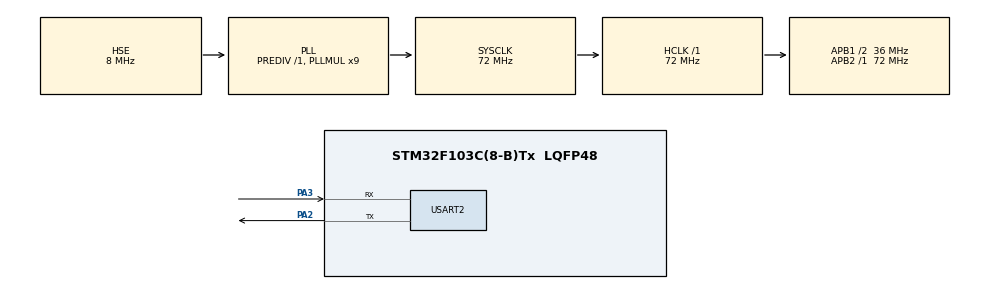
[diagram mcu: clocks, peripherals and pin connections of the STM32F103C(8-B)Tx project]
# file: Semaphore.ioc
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FREERTOS.BinarySemaphores01=myBinarySem01,Dynamic,NULL
FREERTOS.Tasks01=defaultTask,0,128,StartDefaultTask,Default,NULL,Dynamic,NULL,NULL
FREERTOS.configUSE_COUNTING_SEMAPHORES=1
Mcu.Family=STM32F1
Mcu.Name=STM32F103C(8-B)Tx
Mcu.Package=LQFP48
NVIC.PriorityGroup=NVIC_PRIORITYGROUP_4
NVIC.TIM4_IRQn=true\:0\:0\:false\:false\:true\:false\:false\:true
NVIC.TimeBase=TIM4_IRQn
NVIC.TimeBaseIP=TIM4
NVIC.USART2_IRQn=true\:5\:0\:false\:false\:true\:true\:true\:true
PA13.Mode=Serial_Wire
PA13.Signal=SYS_JTMS-SWDIO
PA14.Mode=Serial_Wire
PA14.Signal=SYS_JTCK-SWCLK
PA2.Mode=Asynchronous
PA2.Signal=USART2_TX
PA3.Mode=Asynchronous
PA3.Signal=USART2_RX
PD0-OSC_IN.Mode=HSE-External-Oscillator
PD0-OSC_IN.Signal=RCC_OSC_IN
PD1-OSC_OUT.Mode=HSE-External-Oscillator
PD1-OSC_OUT.Signal=RCC_OSC_OUT
ProjectManager.HeapSize=0x200
ProjectManager.StackSize=0x400
ProjectManager.TargetToolchain=MDK-ARM V5.27
RCC.AHBFreq_Value=72000000
RCC.APB1CLKDivider=RCC_HCLK_DIV2
RCC.APB1Freq_Value=36000000
RCC.APB1TimFreq_Value=72000000
RCC.APB2Freq_Value=72000000
RCC.APB2TimFreq_Value=72000000
RCC.HCLKFreq_Value=72000000
RCC.PLLMUL=RCC_PLL_MUL9
RCC.PLLSourceVirtual=RCC_PLLSOURCE_HSE
RCC.SYSCLKFreq_VALUE=72000000
RCC.SYSCLKSource=RCC_SYSCLKSOURCE_PLLCLK
RCC.USBFreq_Value=72000000
USART2.VirtualMode=VM_ASYNC
VP_FREERTOS_VS_CMSIS_V1.Mode=CMSIS_V1
VP_SYS_VS_tim4.Mode=TIM4
board=custom

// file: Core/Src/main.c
/* USER CODE BEGIN Header */
/* USER CODE END Header */
#include "main.h"
#include "cmsis_os.h"

/* USER CODE BEGIN Includes */
#include <stdio.h>
/* USER CODE END Includes */

UART_HandleTypeDef huart2;

osThreadId defaultTaskHandle;
osSemaphoreId myBinarySem01Handle;
/* USER CODE BEGIN PV */
osSemaphoreId CountingSemHandle;
xTaskHandle AboveNormalHandle;
xTaskHandle HighHandle;
/* USER CODE END PV */

void SystemClock_Config(void);
static void MX_GPIO_Init(void);
static void MX_USART2_UART_Init(void);
void StartDefaultTask(void const * argument);

/* USER CODE BEGIN PFP */
void AboveNormalTask(void *arg);
void HighTask(void *arg);
/* USER CODE END PFP */

/* USER CODE BEGIN 0 */
#ifdef __GNUC__
#define PUTCHAR_PROTOTYPE int __io_putchar(int ch)
#else
#define PUTCHAR_PROTOTYPE int fputc(int ch, FILE *f)
#endif /* __GNUC__ */

/**
  * @brief  Retargets the C library printf function to the USART.
  * @param  None
  * @retval None
  */
PUTCHAR_PROTOTYPE
{
  HAL_UART_Transmit(&huart2, (uint8_t *)&ch, 1, HAL_MAX_DELAY);
  return ch;
}

char data;
/* USER CODE END 0 */

int main(void)
{

  /* MCU Configuration--------------------------------------------------------*/

  /* Reset of all peripherals, Initializes the Flash interface and the Systick. */
  HAL_Init();

  /* Configure the system clock */
  SystemClock_Config();

  /* Initialize all configured peripherals */
  MX_GPIO_Init();
  MX_USART2_UART_Init();
  /* USER CODE BEGIN 2 */
  HAL_UART_Receive_IT(&huart2, (uint8_t *)&data, 1);
  /* USER CODE END 2 */

  /* Create the semaphores(s) */
  /* definition and creation of myBinarySem01 */
  osSemaphoreDef(myBinarySem01);
  myBinarySem01Handle = osSemaphoreCreate(osSemaphore(myBinarySem01), 1);

  /* USER CODE BEGIN RTOS_SEMAPHORES */
  osSemaphoreDef(CoutingSem01);
  CountingSemHandle = osSemaphoreCreate(osSemaphore(CoutingSem01), 3);
  /* add semaphores, ... */
  /* USER CODE END RTOS_SEMAPHORES */

  /* Create the thread(s) */
  /* definition and creation of defaultTask */
  osThreadDef(defaultTask, StartDefaultTask, osPriorityNormal, 0, 128);
  defaultTaskHandle = osThreadCreate(osThread(defaultTask), NULL);

  /* USER CODE BEGIN RTOS_THREADS */
  xTaskCreate(AboveNormalTask, "Task2", 128, NULL, 3 + osPriorityAboveNormal, &AboveNormalHandle);
  xTaskCreate(HighTask, "Task3", 128, NULL, 3+ osPriorityHigh, &HighHandle);

  /* add threads, ... */
  /* USER CODE END RTOS_THREADS */

  /* Start scheduler */
  osKernelStart();

  /* We should never get here as control is now taken by the scheduler */
  /* Infinite loop */

}

void SystemClock_Config(void)
{
  RCC_OscInitTypeDef RCC_OscInitStruct = {0};
  RCC_ClkInitTypeDef RCC_ClkInitStruct = {0};

  /** Initializes the RCC Oscillators according to the specified parameters
  * in the RCC_OscInitTypeDef structure.
  */
  RCC_OscInitStruct.OscillatorType = RCC_OSCILLATORTYPE_HSE;
  RCC_OscInitStruct.HSEState = RCC_HSE_ON;
  RCC_OscInitStruct.HSEPredivValue = RCC_HSE_PREDIV_DIV1;
  RCC_OscInitStruct.HSIState = RCC_HSI_ON;
  RCC_OscInitStruct.PLL.PLLState = RCC_PLL_ON;
  RCC_OscInitStruct.PLL.PLLSource = RCC_PLLSOURCE_HSE;
  RCC_OscInitStruct.PLL.PLLMUL = RCC_PLL_MUL9;
  if (HAL_RCC_OscConfig(&RCC_OscInitStruct) != HAL_OK)
  {
    Error_Handler();
  }
  /** Initializes the CPU, AHB and APB buses clocks
  */
  RCC_ClkInitStruct.ClockType = RCC_CLOCKTYPE_HCLK|RCC_CLOCKTYPE_SYSCLK
                              |RCC_CLOCKTYPE_PCLK1|RCC_CLOCKTYPE_PCLK2;
  RCC_ClkInitStruct.SYSCLKSource = RCC_SYSCLKSOURCE_PLLCLK;
  RCC_ClkInitStruct.AHBCLKDivider = RCC_SYSCLK_DIV1;
  RCC_ClkInitStruct.APB1CLKDivider = RCC_HCLK_DIV2;
  RCC_ClkInitStruct.APB2CLKDivider = RCC_HCLK_DIV1;

  if (HAL_RCC_ClockConfig(&RCC_ClkInitStruct, FLASH_LATENCY_2) != HAL_OK)
  {
    Error_Handler();
  }
}

static void MX_USART2_UART_Init(void)
{

  huart2.Instance = USART2;
  huart2.Init.BaudRate = 115200;
  huart2.Init.WordLength = UART_WORDLENGTH_8B;
  huart2.Init.StopBits = UART_STOPBITS_1;
  huart2.Init.Parity = UART_PARITY_NONE;
  huart2.Init.Mode = UART_MODE_TX_RX;
  huart2.Init.HwFlowCtl = UART_HWCONTROL_NONE;
  huart2.Init.OverSampling = UART_OVERSAMPLING_16;
  if (HAL_UART_Init(&huart2) != HAL_OK)
  {
    Error_Handler();
  }

}

static void MX_GPIO_Init(void)
{

  /* GPIO Ports Clock Enable */
  __HAL_RCC_GPIOD_CLK_ENABLE();
  __HAL_RCC_GPIOA_CLK_ENABLE();

}

/* USER CODE BEGIN 4 */

void HAL_UART_RxCpltCallback(UART_HandleTypeDef *huart)
{
  if(huart->Instance == huart2.Instance)
  {
    HAL_UART_Receive_IT(&huart2, (uint8_t *)&data, 1);
    switch (data)
    {
    case '1':
      osSemaphoreRelease(CountingSemHandle);
      break;
    case '2':
      osSemaphoreRelease(CountingSemHandle);
      osSemaphoreRelease(CountingSemHandle);
      break;
    case '3':
      osSemaphoreRelease(CountingSemHandle);
      osSemaphoreRelease(CountingSemHandle);
      osSemaphoreRelease(CountingSemHandle);
      break;
    default:
      break;
    }
  }
}
void AboveNormalTask(void *arg)
{
  while(1)
  {
    printf("AboveNormal Task waiting Sema and count of Sema available: %d \n",osSemaphoreGetCount(CountingSemHandle));
    osSemaphoreWait(CountingSemHandle, osWaitForever);

    printf("AboveNormal Task get Sema successfully and use Sema \n");
    HAL_Delay(400);
    // printf("AboveNormal Task Give Sema\n");
    // osSemaphoreRelease(myBinarySem01Handle);
    osDelay(100);
  }
}

void HighTask(void *arg)
{
  while(1)
  {
    printf("High Task waiting Sema and count of Sema available: %d \n",osSemaphoreGetCount(CountingSemHandle));
    osSemaphoreWait(CountingSemHandle, osWaitForever);

    printf("High Task get Sema successfully and use Sema \n");
    HAL_Delay(400);
    // printf("High Task Give Sema\n");
    // osSemaphoreRelease(CountingSemHandle);
    osDelay(100);
  }
}
/* USER CODE END 4 */

void StartDefaultTask(void const * argument)
{
  /* USER CODE BEGIN 5 */
  /* Infinite loop */
  for(;;)
  {
    printf("Hello from Default Task\n");
    osDelay(500);
  }
  /* USER CODE END 5 */
}

 /**
  * @brief  Period elapsed callback in non blocking mode
  * @note   This function is called  when TIM4 interrupt took place, inside
  * HAL_TIM_IRQHandler(). It makes a direct call to HAL_IncTick() to increment
  * a global variable "uwTick" used as application time base.
  * @param  htim : TIM handle
  * @retval None
  */
void HAL_TIM_PeriodElapsedCallback(TIM_HandleTypeDef *htim)
{
  if (htim->Instance == TIM4) {
    HAL_IncTick();
  }
}

void Error_Handler(void)
{
}

/************************ (C) COPYRIGHT STMicroelectronics *****END OF FILE****/
